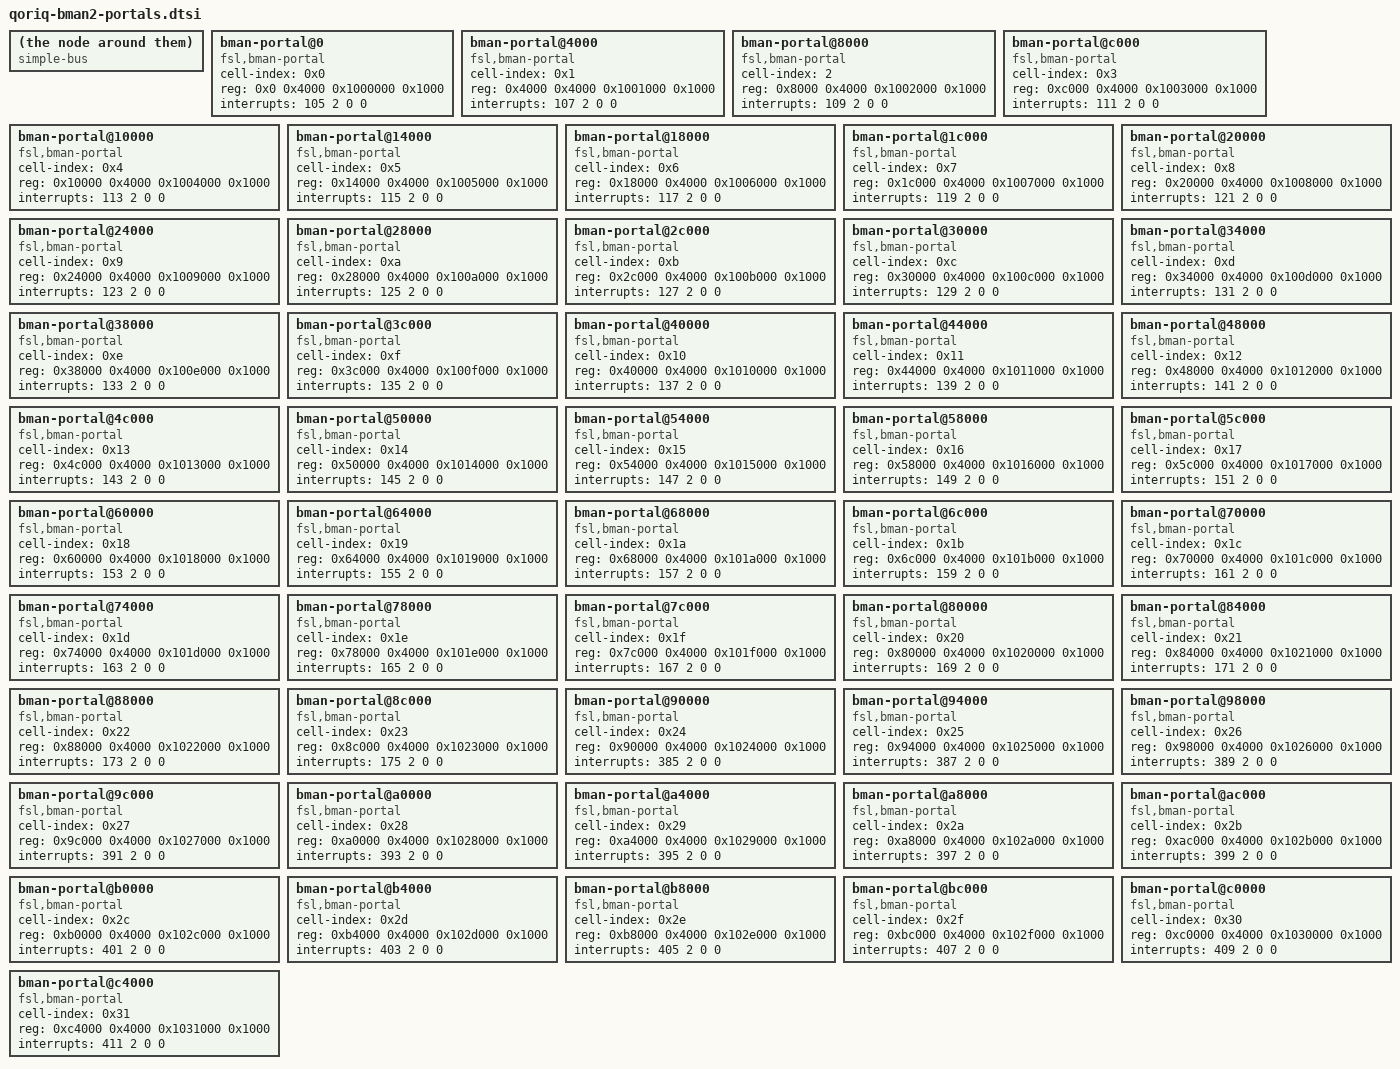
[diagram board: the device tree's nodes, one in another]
/*
 * QorIQ BMan Portal device tree stub for 50 portals
 * i.e BMan2.1
 *
 * Copyright 2011-2012 Freescale Semiconductor Inc.
 *
 * Redistribution and use in source and binary forms, with or without
 * modification, are permitted provided that the following conditions are met:
 *     * Redistributions of source code must retain the above copyright
 *       notice, this list of conditions and the following disclaimer.
 *     * Redistributions in binary form must reproduce the above copyright
 *       notice, this list of conditions and the following disclaimer in the
 *       documentation and/or other materials provided with the distribution.
 *     * Neither the name of Freescale Semiconductor nor the
 *       names of its contributors may be used to endorse or promote products
 *       derived from this software without specific prior written permission.
 *
 *
 * ALTERNATIVELY, this software may be distributed under the terms of the
 * GNU General Public License ("GPL") as published by the Free Software
 * Foundation, either version 2 of that License or (at your option) any
 * later version.
 *
 * THIS SOFTWARE IS PROVIDED BY Freescale Semiconductor ``AS IS'' AND ANY
 * EXPRESS OR IMPLIED WARRANTIES, INCLUDING, BUT NOT LIMITED TO, THE IMPLIED
 * WARRANTIES OF MERCHANTABILITY AND FITNESS FOR A PARTICULAR PURPOSE ARE
 * DISCLAIMED. IN NO EVENT SHALL Freescale Semiconductor BE LIABLE FOR ANY
 * DIRECT, INDIRECT, INCIDENTAL, SPECIAL, EXEMPLARY, OR CONSEQUENTIAL DAMAGES
 * (INCLUDING, BUT NOT LIMITED TO, PROCUREMENT OF SUBSTITUTE GOODS OR SERVICES;
 * LOSS OF USE, DATA, OR PROFITS; OR BUSINESS INTERRUPTION) HOWEVER CAUSED AND
 * ON ANY THEORY OF LIABILITY, WHETHER IN CONTRACT, STRICT LIABILITY, OR TORT
 * (INCLUDING NEGLIGENCE OR OTHERWISE) ARISING IN ANY WAY OUT OF THE USE OF THIS
 * SOFTWARE, EVEN IF ADVISED OF THE POSSIBILITY OF SUCH DAMAGE.
 */

#address-cells = <0x1>;
#size-cells = <0x1>;
compatible = "simple-bus";
bman-portal@0 {
	cell-index = <0x0>;
	compatible = "fsl,bman-portal";
	reg = <0x0 0x4000 0x1000000 0x1000>;
	interrupts = <105 2 0 0>;
};
bman-portal@4000 {
	cell-index = <0x1>;
	compatible = "fsl,bman-portal";
	reg = <0x4000 0x4000 0x1001000 0x1000>;
	interrupts = <107 2 0 0>;
};
bman-portal@8000 {
	cell-index = <2>;
	compatible = "fsl,bman-portal";
	reg = <0x8000 0x4000 0x1002000 0x1000>;
	interrupts = <109 2 0 0>;
};
bman-portal@c000 {
	cell-index = <0x3>;
	compatible = "fsl,bman-portal";
	reg = <0xc000 0x4000 0x1003000 0x1000>;
	interrupts = <111 2 0 0>;
};
bman-portal@10000 {
	cell-index = <0x4>;
	compatible = "fsl,bman-portal";
	reg = <0x10000 0x4000 0x1004000 0x1000>;
	interrupts = <113 2 0 0>;
};
bman-portal@14000 {
	cell-index = <0x5>;
	compatible = "fsl,bman-portal";
	reg = <0x14000 0x4000 0x1005000 0x1000>;
	interrupts = <115 2 0 0>;
};
bman-portal@18000 {
	cell-index = <0x6>;
	compatible = "fsl,bman-portal";
	reg = <0x18000 0x4000 0x1006000 0x1000>;
	interrupts = <117 2 0 0>;
};
bman-portal@1c000 {
	cell-index = <0x7>;
	compatible = "fsl,bman-portal";
	reg = <0x1c000 0x4000 0x1007000 0x1000>;
	interrupts = <119 2 0 0>;
};
bman-portal@20000 {
	cell-index = <0x8>;
	compatible = "fsl,bman-portal";
	reg = <0x20000 0x4000 0x1008000 0x1000>;
	interrupts = <121 2 0 0>;
};
bman-portal@24000 {
	cell-index = <0x9>;
	compatible = "fsl,bman-portal";
	reg = <0x24000 0x4000 0x1009000 0x1000>;
	interrupts = <123 2 0 0>;
};
bman-portal@28000 {
	cell-index = <0xa>;
	compatible = "fsl,bman-portal";
	reg = <0x28000 0x4000 0x100a000 0x1000>;
	interrupts = <125 2 0 0>;
};
bman-portal@2c000 {
	cell-index = <0xb>;
	compatible = "fsl,bman-portal";
	reg = <0x2c000 0x4000 0x100b000 0x1000>;
	interrupts = <127 2 0 0>;
};
bman-portal@30000 {
	cell-index = <0xc>;
	compatible = "fsl,bman-portal";
	reg = <0x30000 0x4000 0x100c000 0x1000>;
	interrupts = <129 2 0 0>;
};
bman-portal@34000 {
	cell-index = <0xd>;
	compatible = "fsl,bman-portal";
	reg = <0x34000 0x4000 0x100d000 0x1000>;
	interrupts = <131 2 0 0>;
};
bman-portal@38000 {
	cell-index = <0xe>;
	compatible = "fsl,bman-portal";
	reg = <0x38000 0x4000 0x100e000 0x1000>;
	interrupts = <133 2 0 0>;
};
bman-portal@3c000 {
	cell-index = <0xf>;
	compatible = "fsl,bman-portal";
	reg = <0x3c000 0x4000 0x100f000 0x1000>;
	interrupts = <135 2 0 0>;
};
bman-portal@40000 {
	cell-index = <0x10>;
	compatible = "fsl,bman-portal";
	reg = <0x40000 0x4000 0x1010000 0x1000>;
	interrupts = <137 2 0 0>;
};
bman-portal@44000 {
	cell-index = <0x11>;
	compatible = "fsl,bman-portal";
	reg = <0x44000 0x4000 0x1011000 0x1000>;
	interrupts = <139 2 0 0>;
};
bman-portal@48000 {
	cell-index = <0x12>;
	compatible = "fsl,bman-portal";
	reg = <0x48000 0x4000 0x1012000 0x1000>;
	interrupts = <141 2 0 0>;
};
bman-portal@4c000 {
	cell-index = <0x13>;
	compatible = "fsl,bman-portal";
	reg = <0x4c000 0x4000 0x1013000 0x1000>;
	interrupts = <143 2 0 0>;
};
bman-portal@50000 {
	cell-index = <0x14>;
	compatible = "fsl,bman-portal";
	reg = <0x50000 0x4000 0x1014000 0x1000>;
	interrupts = <145 2 0 0>;
};
bman-portal@54000 {
	cell-index = <0x15>;
	compatible = "fsl,bman-portal";
	reg = <0x54000 0x4000 0x1015000 0x1000>;
	interrupts = <147 2 0 0>;
};
bman-portal@58000 {
	cell-index = <0x16>;
	compatible = "fsl,bman-portal";
	reg = <0x58000 0x4000 0x1016000 0x1000>;
	interrupts = <149 2 0 0>;
};
bman-portal@5c000 {
	cell-index = <0x17>;
	compatible = "fsl,bman-portal";
	reg = <0x5c000 0x4000 0x1017000 0x1000>;
	interrupts = <151 2 0 0>;
};
bman-portal@60000 {
	cell-index = <0x18>;
	compatible = "fsl,bman-portal";
	reg = <0x60000 0x4000 0x1018000 0x1000>;
	interrupts = <153 2 0 0>;
};
bman-portal@64000 {
	cell-index = <0x19>;
	compatible = "fsl,bman-portal";
	reg = <0x64000 0x4000 0x1019000 0x1000>;
	interrupts = <155 2 0 0>;
};
bman-portal@68000 {
	cell-index = <0x1a>;
	compatible = "fsl,bman-portal";
	reg = <0x68000 0x4000 0x101a000 0x1000>;
	interrupts = <157 2 0 0>;
};
bman-portal@6c000 {
	cell-index = <0x1b>;
	compatible = "fsl,bman-portal";
	reg = <0x6c000 0x4000 0x101b000 0x1000>;
	interrupts = <159 2 0 0>;
};
bman-portal@70000 {
	cell-index = <0x1c>;
	compatible = "fsl,bman-portal";
	reg = <0x70000 0x4000 0x101c000 0x1000>;
	interrupts = <161 2 0 0>;
};
bman-portal@74000 {
	cell-index = <0x1d>;
	compatible = "fsl,bman-portal";
	reg = <0x74000 0x4000 0x101d000 0x1000>;
	interrupts = <163 2 0 0>;
};
bman-portal@78000 {
	cell-index = <0x1e>;
	compatible = "fsl,bman-portal";
	reg = <0x78000 0x4000 0x101e000 0x1000>;
	interrupts = <165 2 0 0>;
};
bman-portal@7c000 {
	cell-index = <0x1f>;
	compatible = "fsl,bman-portal";
	reg = <0x7c000 0x4000 0x101f000 0x1000>;
	interrupts = <167 2 0 0>;
};
bman-portal@80000 {
	cell-index = <0x20>;
	compatible = "fsl,bman-portal";
	reg = <0x80000 0x4000 0x1020000 0x1000>;
	interrupts = <169 2 0 0>;
};
bman-portal@84000 {
	cell-index = <0x21>;
	compatible = "fsl,bman-portal";
	reg = <0x84000 0x4000 0x1021000 0x1000>;
	interrupts = <171 2 0 0>;
};
bman-portal@88000 {
	cell-index = <0x22>;
	compatible = "fsl,bman-portal";
	reg = <0x88000 0x4000 0x1022000 0x1000>;
	interrupts = <173 2 0 0>;
};
bman-portal@8c000 {
	cell-index = <0x23>;
	compatible = "fsl,bman-portal";
	reg = <0x8c000 0x4000 0x1023000 0x1000>;
	interrupts = <175 2 0 0>;
};
bman-portal@90000 {
	cell-index = <0x24>;
	compatible = "fsl,bman-portal";
	reg = <0x90000 0x4000 0x1024000 0x1000>;
	interrupts = <385 2 0 0>;
};
bman-portal@94000 {
	cell-index = <0x25>;
	compatible = "fsl,bman-portal";
	reg = <0x94000 0x4000 0x1025000 0x1000>;
	interrupts = <387 2 0 0>;
};
bman-portal@98000 {
	cell-index = <0x26>;
	compatible = "fsl,bman-portal";
	reg = <0x98000 0x4000 0x1026000 0x1000>;
	interrupts = <389 2 0 0>;
};
bman-portal@9c000 {
	cell-index = <0x27>;
	compatible = "fsl,bman-portal";
	reg = <0x9c000 0x4000 0x1027000 0x1000>;
	interrupts = <391 2 0 0>;
};
bman-portal@a0000 {
	cell-index = <0x28>;
	compatible = "fsl,bman-portal";
	reg = <0xa0000 0x4000 0x1028000 0x1000>;
	interrupts = <393 2 0 0>;
};
bman-portal@a4000 {
	cell-index = <0x29>;
	compatible = "fsl,bman-portal";
	reg = <0xa4000 0x4000 0x1029000 0x1000>;
	interrupts = <395 2 0 0>;
};
bman-portal@a8000 {
	cell-index = <0x2a>;
	compatible = "fsl,bman-portal";
	reg = <0xa8000 0x4000 0x102a000 0x1000>;
	interrupts = <397 2 0 0>;
};
bman-portal@ac000 {
	cell-index = <0x2b>;
	compatible = "fsl,bman-portal";
	reg = <0xac000 0x4000 0x102b000 0x1000>;
	interrupts = <399 2 0 0>;
};
bman-portal@b0000 {
	cell-index = <0x2c>;
	compatible = "fsl,bman-portal";
	reg = <0xb0000 0x4000 0x102c000 0x1000>;
	interrupts = <401 2 0 0>;
};
bman-portal@b4000 {
	cell-index = <0x2d>;
	compatible = "fsl,bman-portal";
	reg = <0xb4000 0x4000 0x102d000 0x1000>;
	interrupts = <403 2 0 0>;
};
bman-portal@b8000 {
	cell-index = <0x2e>;
	compatible = "fsl,bman-portal";
	reg = <0xb8000 0x4000 0x102e000 0x1000>;
	interrupts = <405 2 0 0>;
};
bman-portal@bc000 {
	cell-index = <0x2f>;
	compatible = "fsl,bman-portal";
	reg = <0xbc000 0x4000 0x102f000 0x1000>;
	interrupts = <407 2 0 0>;
};
bman-portal@c0000 {
	cell-index = <0x30>;
	compatible = "fsl,bman-portal";
	reg = <0xc0000 0x4000 0x1030000 0x1000>;
	interrupts = <409 2 0 0>;
};
bman-portal@c4000 {
	cell-index = <0x31>;
	compatible = "fsl,bman-portal";
	reg = <0xc4000 0x4000 0x1031000 0x1000>;
	interrupts = <411 2 0 0>;
};
